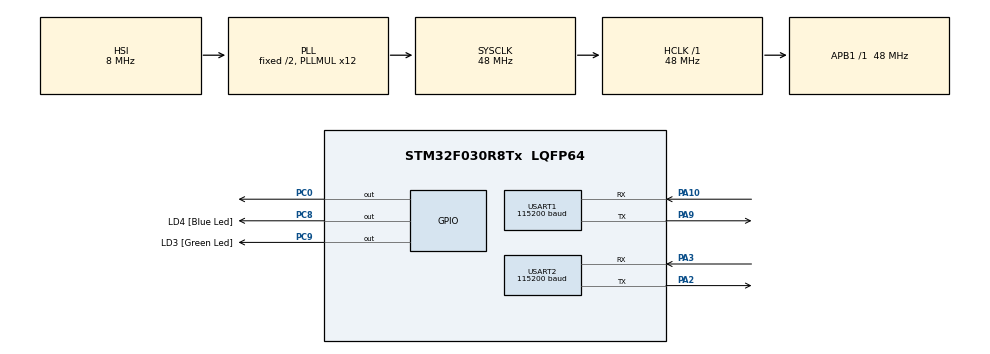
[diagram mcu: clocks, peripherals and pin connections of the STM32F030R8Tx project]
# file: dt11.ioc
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Mcu.Family=STM32F0
PA10.Mode=Asynchronous
PC9.GPIO_Label=LD3 [Green Led]
USART1.BaudRate=115200
PA14.GPIO_Label=SWCLK
TIM6.Prescaler=48
PC8.Signal=GPIO_Output
VP_TIM6_VS_ClockSourceINT.Mode=Enable_Timer
PC0.Signal=GPIO_Output
NVIC.USART2_IRQn=true\:0\:0\:false\:false\:true\:true\:true
USART2.BaudRate=115200
RCC.SYSCLKSource=RCC_SYSCLKSOURCE_PLLCLK
ProjectManager.StackSize=0x400
PC8.GPIO_Label=LD4 [Blue Led]
USART1.VirtualMode-Asynchronous=VM_ASYNC
PA3.Mode=Asynchronous
PA13.Signal=SYS_SWDIO
TIM6.AutoReloadPreload=TIM_AUTORELOAD_PRELOAD_ENABLE
PA9.Mode=Asynchronous
PC0.GPIO_Speed=GPIO_SPEED_FREQ_HIGH
ProjectManager.TargetToolchain=TrueSTUDIO
RCC.HCLKFreq_Value=48000000
PA9.Signal=USART1_TX
RCC.AHBFreq_Value=48000000
board=32F0308DISCOVERY
USART2.VirtualMode-Asynchronous=VM_ASYNC
RCC.PLLMUL=RCC_PLL_MUL12
TIM6.Period=1
Mcu.Name=STM32F030R8Tx
PA2.Signal=USART2_TX
PA13.GPIO_Label=SWDIO
RCC.SYSCLKFreq_VALUE=48000000
Mcu.Package=LQFP64
PA10.Signal=USART1_RX
PA14.Signal=SYS_SWCLK
ProjectManager.HeapSize=0x200
RCC.APB1TimFreq_Value=48000000
PA2.Mode=Asynchronous
PC9.Signal=GPIO_Output
PC0.GPIO_PuPd=GPIO_PULLUP
NVIC.USART1_IRQn=true\:0\:0\:false\:false\:true\:true\:true
RCC.APB1Freq_Value=48000000
PC0.PinState=GPIO_PIN_SET
PA3.Signal=USART2_RX

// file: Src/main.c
/* USER CODE BEGIN Header */
/**
  ******************************************************************************
  * @file           : main.c
  * @brief          : Main program body
  ******************************************************************************
  * @attention
  *
  * <h2><center>&copy; Copyright (c) 2020 STMicroelectronics.
  * All rights reserved.</center></h2>
  *
  * This software component is licensed by ST under BSD 3-Clause license,
  * the "License"; You may not use this file except in compliance with the
  * License. You may obtain a copy of the License at:
  *                        opensource.org/licenses/BSD-3-Clause
  *
  ******************************************************************************
  */
/* USER CODE END Header */

#include "main.h"

/* USER CODE BEGIN Includes */
#include <stdio.h>
#include "dt11.h"
#include "cuart.h"

/* USER CODE END Includes */

TIM_HandleTypeDef htim6;

UART_HandleTypeDef huart1;
UART_HandleTypeDef huart2;

/* USER CODE BEGIN PV */

void HAL_UART_RxCpltCallback(UART_HandleTypeDef *huart)
{
	if (huart->Instance == DEBUG_USART_INSTANCE) {
		cuart_isr(huart);
	}
	else{
		//pn532_isr(huart);
	}

}
/* USER CODE END PV */

void SystemClock_Config(void);
static void MX_GPIO_Init(void);
static void MX_USART1_UART_Init(void);
static void MX_USART2_UART_Init(void);
static void MX_TIM6_Init(void);

int main(void)
{
  /* USER CODE BEGIN 1 */
  setvbuf(stdout,0, _IOLBF, 0);

  /* USER CODE END 1 */

  /* MCU Configuration--------------------------------------------------------*/

  /* Reset of all peripherals, Initializes the Flash interface and the Systick. */
  HAL_Init();

  /* Configure the system clock */
  SystemClock_Config();

  /* Initialize all configured peripherals */
  MX_GPIO_Init();
  MX_USART1_UART_Init();
  MX_USART2_UART_Init();
  MX_TIM6_Init();
  /* USER CODE BEGIN 2 */
	dbg_setup();
	dth11_init();
	dbg_register_task(dth11_read,"read",0);

	printf("dt11 start %s\r\n",__DATE__);
  /* USER CODE END 2 */

  /* Infinite loop */
  while (1)
  {

    /* USER CODE BEGIN 3 */
    dbg_command_scan();
    dth11_listener();

  }
  /* USER CODE END 3 */
}

void SystemClock_Config(void)
{
  RCC_OscInitTypeDef RCC_OscInitStruct = {0};
  RCC_ClkInitTypeDef RCC_ClkInitStruct = {0};
  RCC_PeriphCLKInitTypeDef PeriphClkInit = {0};

  /** Initializes the CPU, AHB and APB busses clocks
  */
  RCC_OscInitStruct.OscillatorType = RCC_OSCILLATORTYPE_HSI;
  RCC_OscInitStruct.HSIState = RCC_HSI_ON;
  RCC_OscInitStruct.HSICalibrationValue = RCC_HSICALIBRATION_DEFAULT;
  RCC_OscInitStruct.PLL.PLLState = RCC_PLL_ON;
  RCC_OscInitStruct.PLL.PLLSource = RCC_PLLSOURCE_HSI;
  RCC_OscInitStruct.PLL.PLLMUL = RCC_PLL_MUL12;
  RCC_OscInitStruct.PLL.PREDIV = RCC_PREDIV_DIV1;
  if (HAL_RCC_OscConfig(&RCC_OscInitStruct) != HAL_OK)
  {
    Error_Handler();
  }
  /** Initializes the CPU, AHB and APB busses clocks
  */
  RCC_ClkInitStruct.ClockType = RCC_CLOCKTYPE_HCLK|RCC_CLOCKTYPE_SYSCLK
                              |RCC_CLOCKTYPE_PCLK1;
  RCC_ClkInitStruct.SYSCLKSource = RCC_SYSCLKSOURCE_PLLCLK;
  RCC_ClkInitStruct.AHBCLKDivider = RCC_SYSCLK_DIV1;
  RCC_ClkInitStruct.APB1CLKDivider = RCC_HCLK_DIV1;

  if (HAL_RCC_ClockConfig(&RCC_ClkInitStruct, FLASH_LATENCY_1) != HAL_OK)
  {
    Error_Handler();
  }
  PeriphClkInit.PeriphClockSelection = RCC_PERIPHCLK_USART1;
  PeriphClkInit.Usart1ClockSelection = RCC_USART1CLKSOURCE_PCLK1;
  if (HAL_RCCEx_PeriphCLKConfig(&PeriphClkInit) != HAL_OK)
  {
    Error_Handler();
  }
}

static void MX_TIM6_Init(void)
{

  htim6.Instance = TIM6;
  htim6.Init.Prescaler = 48;
  htim6.Init.CounterMode = TIM_COUNTERMODE_UP;
  htim6.Init.Period = 10000;
  htim6.Init.AutoReloadPreload = TIM_AUTORELOAD_PRELOAD_ENABLE;
  if (HAL_TIM_Base_Init(&htim6) != HAL_OK)
  {
    Error_Handler();
  }

}

static void MX_USART1_UART_Init(void)
{

  huart1.Instance = USART1;
  huart1.Init.BaudRate = 115200;
  huart1.Init.WordLength = UART_WORDLENGTH_8B;
  huart1.Init.StopBits = UART_STOPBITS_1;
  huart1.Init.Parity = UART_PARITY_NONE;
  huart1.Init.Mode = UART_MODE_TX_RX;
  huart1.Init.HwFlowCtl = UART_HWCONTROL_NONE;
  huart1.Init.OverSampling = UART_OVERSAMPLING_16;
  huart1.Init.OneBitSampling = UART_ONE_BIT_SAMPLE_DISABLE;
  huart1.AdvancedInit.AdvFeatureInit = UART_ADVFEATURE_NO_INIT;
  if (HAL_UART_Init(&huart1) != HAL_OK)
  {
    Error_Handler();
  }

}

static void MX_USART2_UART_Init(void)
{

  huart2.Instance = USART2;
  huart2.Init.BaudRate = 115200;
  huart2.Init.WordLength = UART_WORDLENGTH_8B;
  huart2.Init.StopBits = UART_STOPBITS_1;
  huart2.Init.Parity = UART_PARITY_NONE;
  huart2.Init.Mode = UART_MODE_TX_RX;
  huart2.Init.HwFlowCtl = UART_HWCONTROL_NONE;
  huart2.Init.OverSampling = UART_OVERSAMPLING_16;
  huart2.Init.OneBitSampling = UART_ONE_BIT_SAMPLE_DISABLE;
  huart2.AdvancedInit.AdvFeatureInit = UART_ADVFEATURE_NO_INIT;
  if (HAL_UART_Init(&huart2) != HAL_OK)
  {
    Error_Handler();
  }

}

static void MX_GPIO_Init(void)
{
  GPIO_InitTypeDef GPIO_InitStruct = {0};

  /* GPIO Ports Clock Enable */
  __HAL_RCC_GPIOC_CLK_ENABLE();
  __HAL_RCC_GPIOA_CLK_ENABLE();

  /*Configure GPIO pin Output Level */
  HAL_GPIO_WritePin(GPIOC, GPIO_PIN_0, GPIO_PIN_SET);

  /*Configure GPIO pin Output Level */
  HAL_GPIO_WritePin(GPIOC, LD4_Pin|LD3_Pin, GPIO_PIN_RESET);

  /*Configure GPIO pin : PC0 */
  GPIO_InitStruct.Pin = GPIO_PIN_0;
  GPIO_InitStruct.Mode = GPIO_MODE_OUTPUT_PP;
  GPIO_InitStruct.Pull = GPIO_NOPULL;
  GPIO_InitStruct.Speed = GPIO_SPEED_FREQ_HIGH;
  HAL_GPIO_Init(GPIOC, &GPIO_InitStruct);

  /*Configure GPIO pins : LD4_Pin LD3_Pin */
  GPIO_InitStruct.Pin = LD4_Pin|LD3_Pin;
  GPIO_InitStruct.Mode = GPIO_MODE_OUTPUT_PP;
  GPIO_InitStruct.Pull = GPIO_NOPULL;
  GPIO_InitStruct.Speed = GPIO_SPEED_FREQ_LOW;
  HAL_GPIO_Init(GPIOC, &GPIO_InitStruct);

}

void Error_Handler(void)
{
}

/************************ (C) COPYRIGHT STMicroelectronics *****END OF FILE****/
